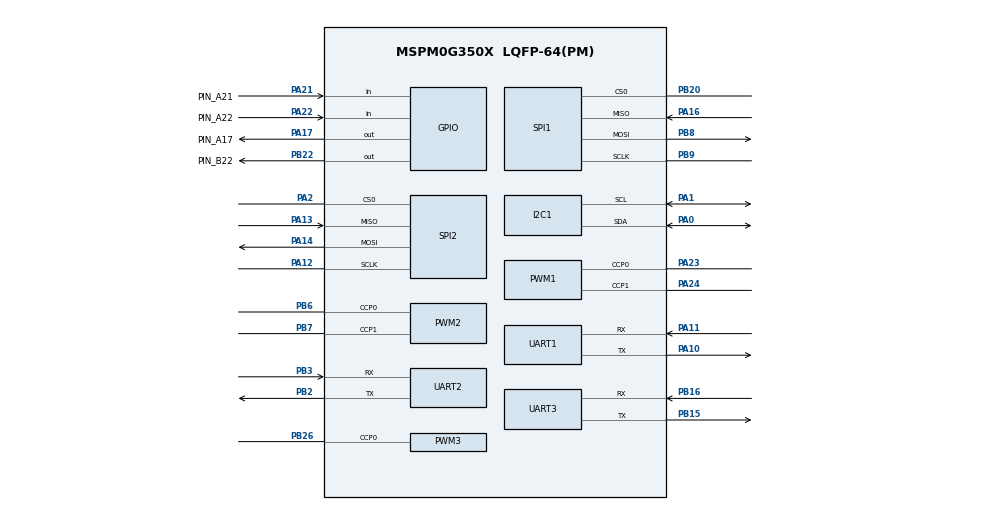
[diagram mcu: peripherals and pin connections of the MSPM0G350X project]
/**
 * @cliArgs --device "MSPM0G350X" --part "Default" --package "LQFP-64(PM)" --product "mspm0_sdk@2.07.00.05"
 * @versions {"tool":"1.25.0+4268"}
 */

/**
 * Import the modules used in this configuration.
 */
const ADC12         = scripting.addModule("/ti/driverlib/ADC12", {}, false);
const ADC121        = ADC12.addInstance();
const GPIO          = scripting.addModule("/ti/driverlib/GPIO", {}, false);
const GPIO1         = GPIO.addInstance();
const GPIO2         = GPIO.addInstance();
const GPIO3         = GPIO.addInstance();
const GPIO4         = GPIO.addInstance();
const GPIO5         = GPIO.addInstance();
const GPIO6         = GPIO.addInstance();
const I2C           = scripting.addModule("/ti/driverlib/I2C", {}, false);
const I2C1          = I2C.addInstance();
const PWM           = scripting.addModule("/ti/driverlib/PWM", {}, false);
const PWM1          = PWM.addInstance();
const PWM2          = PWM.addInstance();
const PWM3          = PWM.addInstance();
const SPI           = scripting.addModule("/ti/driverlib/SPI", {}, false);
const SPI1          = SPI.addInstance();
const SPI2          = SPI.addInstance();
const SYSCTL        = scripting.addModule("/ti/driverlib/SYSCTL");
const SYSTICK       = scripting.addModule("/ti/driverlib/SYSTICK");
const UART          = scripting.addModule("/ti/driverlib/UART", {}, false);
const UART1         = UART.addInstance();
const UART2         = UART.addInstance();
const UART3         = UART.addInstance();
const ProjectConfig = scripting.addModule("/ti/project_config/ProjectConfig");

/**
 * Write custom configuration values to the imported modules.
 */
const gate7  = system.clockTree["MFCLKGATE"];
gate7.enable = true;

ADC121.$name                             = "ADC_POWER";
ADC121.peripheral.adcPin0.$assign        = "PA15";
ADC121.adcPin0Config.hideOutputInversion = scripting.forceWrite(false);
ADC121.adcPin0Config.$name               = "ti_driverlib_gpio_GPIOPinGeneric6";

const Board = scripting.addModule("/ti/driverlib/Board", {}, false);

GPIO1.port                          = "PORTB";
GPIO1.$name                         = "GPIO_OTHER";
GPIO1.associatedPins.create(3);
GPIO1.associatedPins[0].assignedPin = "22";
GPIO1.associatedPins[0].$name       = "PIN_B22";
GPIO1.associatedPins[0].pin.$assign = "PB22";
GPIO1.associatedPins[1].$name       = "PIN_B1";
GPIO1.associatedPins[1].assignedPin = "1";
GPIO1.associatedPins[2].$name       = "PIN_B0";
GPIO1.associatedPins[2].assignedPin = "0";

GPIO2.$name                               = "GPIO_LEFT";
GPIO2.port                                = "PORTA";
GPIO2.associatedPins.create(4);
GPIO2.associatedPins[0].$name             = "PIN_A21";
GPIO2.associatedPins[0].direction         = "INPUT";
GPIO2.associatedPins[0].assignedPin       = "21";
GPIO2.associatedPins[0].interruptEn       = true;
GPIO2.associatedPins[0].interruptPriority = "0";
GPIO2.associatedPins[0].polarity          = "RISE";
GPIO2.associatedPins[0].pin.$assign       = "PA21";
GPIO2.associatedPins[1].$name             = "PIN_A22";
GPIO2.associatedPins[1].direction         = "INPUT";
GPIO2.associatedPins[1].assignedPin       = "22";
GPIO2.associatedPins[1].interruptEn       = true;
GPIO2.associatedPins[1].polarity          = "RISE";
GPIO2.associatedPins[1].interruptPriority = "0";
GPIO2.associatedPins[1].pin.$assign       = "PA22";
GPIO2.associatedPins[2].$name             = "PIN_A17";
GPIO2.associatedPins[2].assignedPin       = "17";
GPIO2.associatedPins[2].pin.$assign       = "PA17";
GPIO2.associatedPins[3].$name             = "PIN_A18";
GPIO2.associatedPins[3].assignedPin       = "18";

GPIO3.$name                               = "GPIO_RIGHT";
GPIO3.port                                = "PORTA";
GPIO3.associatedPins.create(4);
GPIO3.associatedPins[0].$name             = "PIN_A28";
GPIO3.associatedPins[0].assignedPin       = "28";
GPIO3.associatedPins[1].$name             = "PIN_A27";
GPIO3.associatedPins[1].assignedPin       = "27";
GPIO3.associatedPins[2].$name             = "PIN_A26";
GPIO3.associatedPins[2].direction         = "INPUT";
GPIO3.associatedPins[2].assignedPin       = "26";
GPIO3.associatedPins[2].interruptEn       = true;
GPIO3.associatedPins[2].polarity          = "RISE";
GPIO3.associatedPins[2].interruptPriority = "0";
GPIO3.associatedPins[3].$name             = "PIN_A25";
GPIO3.associatedPins[3].direction         = "INPUT";
GPIO3.associatedPins[3].assignedPin       = "25";
GPIO3.associatedPins[3].interruptEn       = true;
GPIO3.associatedPins[3].interruptPriority = "0";
GPIO3.associatedPins[3].polarity          = "RISE";

GPIO4.$name                               = "BUTTON";
GPIO4.port                                = "PORTA";
GPIO4.associatedPins.create(3);
GPIO4.associatedPins[0].$name             = "PIN_A29";
GPIO4.associatedPins[0].assignedPin       = "29";
GPIO4.associatedPins[0].direction         = "INPUT";
GPIO4.associatedPins[0].interruptPriority = "0";
GPIO4.associatedPins[0].interruptEn       = true;
GPIO4.associatedPins[0].polarity          = "RISE";
GPIO4.associatedPins[1].$name             = "PIN_A30";
GPIO4.associatedPins[1].direction         = "INPUT";
GPIO4.associatedPins[1].assignedPin       = "30";
GPIO4.associatedPins[1].interruptEn       = true;
GPIO4.associatedPins[1].interruptPriority = "0";
GPIO4.associatedPins[1].polarity          = "RISE";
GPIO4.associatedPins[2].$name             = "PIN_A31";
GPIO4.associatedPins[2].direction         = "INPUT";
GPIO4.associatedPins[2].assignedPin       = "31";
GPIO4.associatedPins[2].interruptEn       = true;
GPIO4.associatedPins[2].interruptPriority = "0";
GPIO4.associatedPins[2].polarity          = "RISE";

GPIO5.$name                                 = "GPIO_SPI";
GPIO5.port                                  = "PORTB";
GPIO5.associatedPins.create(2);
GPIO5.associatedPins[0].assignedPin         = "11";
GPIO5.associatedPins[0].$name               = "PIN_B11";
GPIO5.associatedPins[1].$name               = "PIN_B14";
GPIO5.associatedPins[1].assignedPin         = "14";
GPIO5.associatedPins[1].assignedPortSegment = "Lower";

GPIO6.$name                               = "GPIO_GYRO";
GPIO6.associatedPins.create(4);
GPIO6.associatedPins[0].$name             = "PIN_A9";
GPIO6.associatedPins[0].assignedPort      = "PORTA";
GPIO6.associatedPins[0].assignedPin       = "9";
GPIO6.associatedPins[1].$name             = "PIN_A8";
GPIO6.associatedPins[1].assignedPort      = "PORTA";
GPIO6.associatedPins[1].assignedPin       = "8";
GPIO6.associatedPins[2].$name             = "PIN_B5";
GPIO6.associatedPins[2].direction         = "INPUT";
GPIO6.associatedPins[2].assignedPort      = "PORTB";
GPIO6.associatedPins[2].assignedPin       = "5";
GPIO6.associatedPins[2].interruptEn       = true;
GPIO6.associatedPins[2].interruptPriority = "0";
GPIO6.associatedPins[2].polarity          = "RISE";
GPIO6.associatedPins[3].$name             = "PIN_B4";
GPIO6.associatedPins[3].direction         = "INPUT";
GPIO6.associatedPins[3].assignedPort      = "PORTB";
GPIO6.associatedPins[3].assignedPin       = "4";
GPIO6.associatedPins[3].interruptEn       = true;
GPIO6.associatedPins[3].interruptPriority = "0";
GPIO6.associatedPins[3].polarity          = "RISE";

I2C1.$name                             = "I2C_SENSOR";
I2C1.peripheral.$assign                = "I2C0";
I2C1.peripheral.sdaPin.$assign         = "PA0";
I2C1.peripheral.sclPin.$assign         = "PA1";
I2C1.sdaPinConfig.hideOutputInversion  = scripting.forceWrite(false);
I2C1.sdaPinConfig.onlyInternalResistor = scripting.forceWrite(false);
I2C1.sdaPinConfig.passedPeripheralType = scripting.forceWrite("Digital");
I2C1.sdaPinConfig.$name                = "ti_driverlib_gpio_GPIOPinGeneric7";
I2C1.sclPinConfig.hideOutputInversion  = scripting.forceWrite(false);
I2C1.sclPinConfig.onlyInternalResistor = scripting.forceWrite(false);
I2C1.sclPinConfig.passedPeripheralType = scripting.forceWrite("Digital");
I2C1.sclPinConfig.$name                = "ti_driverlib_gpio_GPIOPinGeneric8";

PWM1.clockDivider                       = 8;
PWM1.clockPrescale                      = 40;
PWM1.timerStartTimer                    = true;
PWM1.$name                              = "PWM_MOTOR";
PWM1.peripheral.$assign                 = "TIMG0";
PWM1.peripheral.ccp0Pin.$assign         = "PA23";
PWM1.peripheral.ccp1Pin.$assign         = "PA24";
PWM1.PWM_CHANNEL_0.$name                = "ti_driverlib_pwm_PWMTimerCC0";
PWM1.PWM_CHANNEL_1.$name                = "ti_driverlib_pwm_PWMTimerCC1";
PWM1.ccp0PinConfig.direction            = scripting.forceWrite("OUTPUT");
PWM1.ccp0PinConfig.hideOutputInversion  = scripting.forceWrite(false);
PWM1.ccp0PinConfig.onlyInternalResistor = scripting.forceWrite(false);
PWM1.ccp0PinConfig.passedPeripheralType = scripting.forceWrite("Digital");
PWM1.ccp0PinConfig.$name                = "ti_driverlib_gpio_GPIOPinGeneric0";
PWM1.ccp1PinConfig.direction            = scripting.forceWrite("OUTPUT");
PWM1.ccp1PinConfig.hideOutputInversion  = scripting.forceWrite(false);
PWM1.ccp1PinConfig.onlyInternalResistor = scripting.forceWrite(false);
PWM1.ccp1PinConfig.passedPeripheralType = scripting.forceWrite("Digital");
PWM1.ccp1PinConfig.$name                = "ti_driverlib_gpio_GPIOPinGeneric1";

PWM2.$name                              = "PWM_OTHER";
PWM2.timerStartTimer                    = true;
PWM2.clockDivider                       = 8;
PWM2.clockPrescale                      = 100;
PWM2.peripheral.$assign                 = "TIMG6";
PWM2.peripheral.ccp0Pin.$assign         = "PB6";
PWM2.peripheral.ccp1Pin.$assign         = "PB7";
PWM2.PWM_CHANNEL_0.$name                = "ti_driverlib_pwm_PWMTimerCC2";
PWM2.PWM_CHANNEL_1.$name                = "ti_driverlib_pwm_PWMTimerCC3";
PWM2.ccp0PinConfig.direction            = scripting.forceWrite("OUTPUT");
PWM2.ccp0PinConfig.hideOutputInversion  = scripting.forceWrite(false);
PWM2.ccp0PinConfig.onlyInternalResistor = scripting.forceWrite(false);
PWM2.ccp0PinConfig.passedPeripheralType = scripting.forceWrite("Digital");
PWM2.ccp0PinConfig.$name                = "ti_driverlib_gpio_GPIOPinGeneric2";
PWM2.ccp1PinConfig.direction            = scripting.forceWrite("OUTPUT");
PWM2.ccp1PinConfig.hideOutputInversion  = scripting.forceWrite(false);
PWM2.ccp1PinConfig.onlyInternalResistor = scripting.forceWrite(false);
PWM2.ccp1PinConfig.passedPeripheralType = scripting.forceWrite("Digital");
PWM2.ccp1PinConfig.$name                = "ti_driverlib_gpio_GPIOPinGeneric3";

PWM3.$name                              = "PWM_SPI";
PWM3.timerStartTimer                    = true;
PWM3.clockDivider                       = 8;
PWM3.clockPrescale                      = 40;
PWM3.ccIndex                            = [0];
PWM3.PWM_CHANNEL_0.$name                = "ti_driverlib_pwm_PWMTimerCC4";
PWM3.ccp0PinConfig.direction            = scripting.forceWrite("OUTPUT");
PWM3.ccp0PinConfig.hideOutputInversion  = scripting.forceWrite(false);
PWM3.ccp0PinConfig.onlyInternalResistor = scripting.forceWrite(false);
PWM3.ccp0PinConfig.passedPeripheralType = scripting.forceWrite("Digital");
PWM3.ccp0PinConfig.$name                = "ti_driverlib_gpio_GPIOPinGeneric15";
PWM3.peripheral.$assign                 = "TIMA1";
PWM3.peripheral.ccp0Pin.$assign         = "PB26";

SPI1.$name                      = "SPI_0";
SPI1.peripheral.sclkPin.$assign = "PB9";
SPI1.peripheral.mosiPin.$assign = "PB8";
SPI1.peripheral.misoPin.$assign = "PA16";
SPI1.peripheral.cs0Pin.$assign  = "PB20";
SPI1.sclkPinConfig.$name        = "ti_driverlib_gpio_GPIOPinGeneric19";
SPI1.mosiPinConfig.$name        = "ti_driverlib_gpio_GPIOPinGeneric20";
SPI1.misoPinConfig.$name        = "ti_driverlib_gpio_GPIOPinGeneric21";
SPI1.cs0PinConfig.$name         = "ti_driverlib_gpio_GPIOPinGeneric22";

SPI2.$name                      = "SPI_1";
SPI2.peripheral.$assign         = "SPI0";
SPI2.peripheral.sclkPin.$assign = "PA12";
SPI2.peripheral.mosiPin.$assign = "PA14";
SPI2.peripheral.misoPin.$assign = "PA13";
SPI2.peripheral.cs0Pin.$assign  = "PA2";
SPI2.sclkPinConfig.$name        = "ti_driverlib_gpio_GPIOPinGeneric16";
SPI2.mosiPinConfig.$name        = "ti_driverlib_gpio_GPIOPinGeneric17";
SPI2.misoPinConfig.$name        = "ti_driverlib_gpio_GPIOPinGeneric18";
SPI2.cs0PinConfig.$name         = "ti_driverlib_gpio_GPIOPinGeneric23";

SYSCTL.forceDefaultClkConfig = true;
SYSCTL.clockTreeEn           = true;

SYSTICK.periodEnable      = true;
SYSTICK.period            = 32000;
SYSTICK.interruptEnable   = true;
SYSTICK.interruptPriority = "0";
SYSTICK.systickEnable     = true;

UART1.$name                    = "UART_0";
UART1.peripheral.$assign       = "UART0";
UART1.peripheral.rxPin.$assign = "PA11";
UART1.peripheral.txPin.$assign = "PA10";
UART1.txPinConfig.$name        = "ti_driverlib_gpio_GPIOPinGeneric4";
UART1.rxPinConfig.$name        = "ti_driverlib_gpio_GPIOPinGeneric5";

UART2.$name                            = "UART_3";
UART2.peripheral.$assign               = "UART3";
UART2.peripheral.rxPin.$assign         = "PB3";
UART2.peripheral.txPin.$assign         = "PB2";
UART2.txPinConfig.direction            = scripting.forceWrite("OUTPUT");
UART2.txPinConfig.hideOutputInversion  = scripting.forceWrite(false);
UART2.txPinConfig.onlyInternalResistor = scripting.forceWrite(false);
UART2.txPinConfig.passedPeripheralType = scripting.forceWrite("Digital");
UART2.txPinConfig.$name                = "ti_driverlib_gpio_GPIOPinGeneric11";
UART2.rxPinConfig.hideOutputInversion  = scripting.forceWrite(false);
UART2.rxPinConfig.onlyInternalResistor = scripting.forceWrite(false);
UART2.rxPinConfig.passedPeripheralType = scripting.forceWrite("Digital");
UART2.rxPinConfig.$name                = "ti_driverlib_gpio_GPIOPinGeneric12";

UART3.$name                    = "UART_2";
UART3.peripheral.$assign       = "UART2";
UART3.peripheral.rxPin.$assign = "PB16";
UART3.peripheral.txPin.$assign = "PB15";
UART3.txPinConfig.$name        = "ti_driverlib_gpio_GPIOPinGeneric13";
UART3.rxPinConfig.$name        = "ti_driverlib_gpio_GPIOPinGeneric14";

/**
 * Pinmux solution for unlocked pins/peripherals. This ensures that minor changes to the automatic solver in a future
 * version of the tool will not impact the pinmux you originally saw.  These lines can be completely deleted in order to
 * re-solve from scratch.
 */
ADC121.peripheral.$suggestSolution           = "ADC1";
Board.peripheral.$suggestSolution            = "DEBUGSS";
Board.peripheral.swclkPin.$suggestSolution   = "PA20";
Board.peripheral.swdioPin.$suggestSolution   = "PA19";
GPIO1.associatedPins[1].pin.$suggestSolution = "PB1";
GPIO1.associatedPins[2].pin.$suggestSolution = "PB0";
GPIO2.associatedPins[3].pin.$suggestSolution = "PA18";
GPIO3.associatedPins[0].pin.$suggestSolution = "PA28";
GPIO3.associatedPins[1].pin.$suggestSolution = "PA27";
GPIO3.associatedPins[2].pin.$suggestSolution = "PA26";
GPIO3.associatedPins[3].pin.$suggestSolution = "PA25";
GPIO4.associatedPins[0].pin.$suggestSolution = "PA29";
GPIO4.associatedPins[1].pin.$suggestSolution = "PA30";
GPIO4.associatedPins[2].pin.$suggestSolution = "PA31";
GPIO5.associatedPins[0].pin.$suggestSolution = "PB11";
GPIO5.associatedPins[1].pin.$suggestSolution = "PB14";
GPIO6.associatedPins[0].pin.$suggestSolution = "PA9";
GPIO6.associatedPins[1].pin.$suggestSolution = "PA8";
GPIO6.associatedPins[2].pin.$suggestSolution = "PB5";
GPIO6.associatedPins[3].pin.$suggestSolution = "PB4";
SPI1.peripheral.$suggestSolution             = "SPI1";
